# STM32H7B3x register map
File version: 2.2
CPU: CM7 r0p1, little endian, MPU, FPU, 4 interrupt priority bits
Registers are 32-bit, read-write, reset 0x0 unless marked. A register's access mark holds for its fields unless they carry their own. Offsets are from the block's base; [hi:lo] are bit positions.

## USART1 — Universal synchronous asynchronous receiver transmitter
Base 0x40011000
Same registers: USART2 0x40004400, USART3 0x40004800, UART4 0x40004C00, UART5 0x40005000, UART7 0x40007800, UART8 0x40007C00, USART6 0x40011400, UART9 0x40011800, USART10 0x40011C00
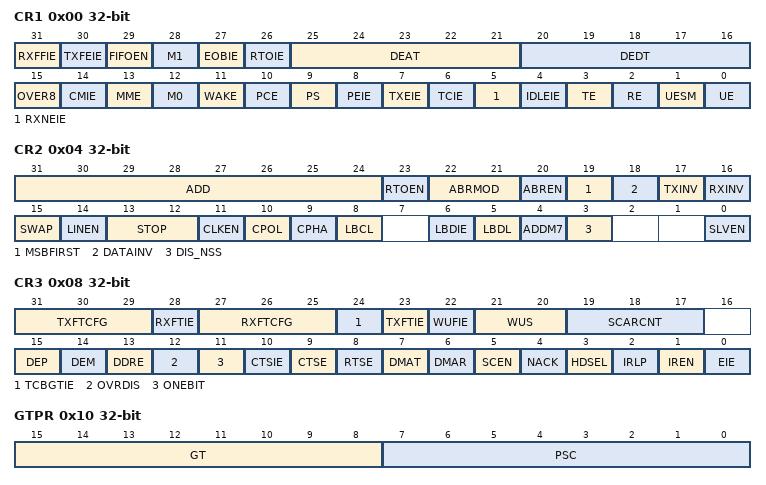
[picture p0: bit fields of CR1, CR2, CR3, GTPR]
0x00 CR1 — Control register 1
  [31] RXFFIE — RXFIFO Full interrupt enable
  [30] TXFEIE — TXFIFO empty interrupt enable
  [29] FIFOEN — FIFO mode enable
  [28] M1 — Word length
    0=M0 (Use M0 to set the data bits); 1=Bit7 (1 start bit, 7 data bits, n stop bits)
  [27] EOBIE — End of Block interrupt enable
    0=Disabled (Interrupt is inhibited); 1=Enabled (A USART interrupt is generated when the EOBF flag is set in the ISR register)
  [26] RTOIE — Receiver timeout interrupt enable
    0=Disabled (Interrupt is inhibited); 1=Enabled (An USART interrupt is generated when the RTOF bit is set in the ISR register)
  [25:21] DEAT — Driver Enable assertion time
  [20:16] DEDT — Driver Enable de-assertion time
  [15] OVER8 — Oversampling mode
    0=Oversampling16 (Oversampling by 16); 1=Oversampling8 (Oversampling by 8)
  [14] CMIE — Character match interrupt enable
    0=Disabled (Interrupt is disabled); 1=Enabled (Interrupt is generated when the CMF bit is set in the ISR register)
  [13] MME — Mute mode enable
    0=Disabled (Receiver in active mode permanently); 1=Enabled (Receiver can switch between mute mode and active mode)
  [12] M0 — Word length
    0=Bit8 (1 start bit, 8 data bits, n stop bits); 1=Bit9 (1 start bit, 9 data bits, n stop bits)
  [11] WAKE — Receiver wakeup method
    0=Idle line; 1=Address mask
  [10] PCE — Parity control enable
    0=Disabled (Parity control disabled); 1=Enabled (Parity control enabled)
  [9] PS — Parity selection
    0=Even parity; 1=Odd (Odd parity)
  [8] PEIE — PE interrupt enable
    0=Disabled (Interrupt is disabled); 1=Enabled (Interrupt is generated whenever PE=1 in the ISR register)
  [7] TXEIE — interrupt enable
    0=Disabled (Interrupt is disabled); 1=Enabled (Interrupt is generated whenever TXE=1 in the ISR register)
  [6] TCIE — Transmission complete interrupt enable
    0=Disabled (Interrupt is disabled); 1=Enabled (Interrupt is generated whenever TC=1 in the ISR register)
  [5] RXNEIE — RXNE interrupt enable
    0=Disabled (Interrupt is disabled); 1=Enabled (Interrupt is generated whenever ORE=1 or RXNE=1 in the ISR register)
  [4] IDLEIE — IDLE interrupt enable
    0=Disabled (Interrupt is disabled); 1=Enabled (Interrupt is generated whenever IDLE=1 in the ISR register)
  [3] TE — Transmitter enable
    0=Disabled (Transmitter is disabled); 1=Enabled (Transmitter is enabled)
  [2] RE — Receiver enable
    0=Disabled (Receiver is disabled); 1=Enabled (Receiver is enabled)
  [1] UESM — USART enable in Stop mode
    0=Disabled (USART not able to wake up the MCU from Stop mode); 1=Enabled (USART able to wake up the MCU from Stop mode)
  [0] UE — USART enable
    0=Disabled (UART is disabled); 1=Enabled (UART is enabled)
0x04 CR2 — Control register 2
  [31:24] ADD — Address of the USART node
  [23] RTOEN — Receiver timeout enable
    0=Disabled (Receiver timeout feature disabled); 1=Enabled (Receiver timeout feature enabled)
  [22:21] ABRMOD — Auto baud rate mode
    0=Start (Measurement of the start bit is used to detect the baud rate); 1=Edge (Falling edge to falling edge measurement); 2=Frame7F (0x7F frame detection); 3=Frame55 (0x55 frame detection)
  [20] ABREN — Auto baud rate enable
    0=Disabled (Auto baud rate detection is disabled); 1=Enabled (Auto baud rate detection is enabled)
  [19] MSBFIRST — Most significant bit first
    0=LSB (data is transmitted/received with data bit 0 first, following the start bit); 1=MSB (data is transmitted/received with MSB (bit 7/8/9) first, following the start bit)
  [18] DATAINV — Binary data inversion
    0=Positive (Logical data from the data register are send/received in positive/direct logic); 1=Negative (Logical data from the data register are send/received in negative/inverse logic)
  [17] TXINV — TX pin active level inversion
    0=Standard (TX pin signal works using the standard logic levels); 1=Inverted (TX pin signal values are inverted)
  [16] RXINV — RX pin active level inversion
    0=Standard (RX pin signal works using the standard logic levels); 1=Inverted (RX pin signal values are inverted)
  [15] SWAP — Swap TX/RX pins
    0=Standard (TX/RX pins are used as defined in standard pinout); 1=Swapped (The TX and RX pins functions are swapped)
  [14] LINEN — LIN mode enable
    0=Disabled (LIN mode disabled); 1=Enabled (LIN mode enabled)
  [13:12] STOP — STOP bits
    0=1 stop bit; 1=Stop0p5 (0.5 stop bit); 2=2 stop bit; 3=Stop1p5 (1.5 stop bit)
  [11] CLKEN — Clock enable
    0=Disabled (CK pin disabled); 1=Enabled (CK pin enabled)
  [10] CPOL — Clock polarity
    0=Low (Steady low value on CK pin outside transmission window); 1=High (Steady high value on CK pin outside transmission window)
  [9] CPHA — Clock phase
    0=First (The first clock transition is the first data capture edge); 1=Second (The second clock transition is the first data capture edge)
  [8] LBCL — Last bit clock pulse
    0=NotOutput (The clock pulse of the last data bit is not output to the CK pin); 1=Output (The clock pulse of the last data bit is output to the CK pin)
  [6] LBDIE — LIN break detection interrupt enable
    0=Disabled (Interrupt is inhibited); 1=Enabled (An interrupt is generated whenever LBDF=1 in the ISR register)
  [5] LBDL — LIN break detection length
    0=Bit10 (10-bit break detection); 1=Bit11 (11-bit break detection)
  [4] ADDM7 — 7-bit Address Detection/4-bit Address Detection
    0=Bit4 (4-bit address detection); 1=Bit7 (7-bit address detection)
  [3] DIS_NSS — When the DSI_NSS bit is set, the NSS pin input is ignored
  [0] SLVEN — Synchronous Slave mode enable
0x08 CR3 — Control register 3
  [31:29] TXFTCFG — TXFIFO threshold configuration
  [28] RXFTIE — RXFIFO threshold interrupt enable
  [27:25] RXFTCFG — Receive FIFO threshold configuration
  [24] TCBGTIE — Transmission Complete before guard time, interrupt enable
  [23] TXFTIE — TXFIFO threshold interrupt enable
  [22] WUFIE — Wakeup from Stop mode interrupt enable
    0=Disabled (Interrupt is inhibited); 1=Enabled (An USART interrupt is generated whenever WUF=1 in the ISR register)
  [21:20] WUS — Wakeup from Stop mode interrupt flag selection
    0=Address (WUF active on address match); 2=Start (WuF active on Start bit detection); 3=RXNE (WUF active on RXNE)
  [19:17] SCARCNT — Smartcard auto-retry count
  [15] DEP — Driver enable polarity selection
    0=High (DE signal is active high); 1=Low (DE signal is active low)
  [14] DEM — Driver enable mode
    0=Disabled (DE function is disabled); 1=Enabled (The DE signal is output on the RTS pin)
  [13] DDRE — DMA Disable on Reception Error
    0=NotDisabled (DMA is not disabled in case of reception error); 1=Disabled (DMA is disabled following a reception error)
  [12] OVRDIS — Overrun Disable
    0=Enabled (Overrun Error Flag, ORE, is set when received data is not read before receiving new data); 1=Disabled (Overrun functionality is disabled. If new data is received while the RXNE flag is still set the ORE flag is not set and the new received data overwrites the previous content of the RDR register)
  [11] ONEBIT — One sample bit method enable
    0=Sample3 (Three sample bit method); 1=Sample1 (One sample bit method)
  [10] CTSIE — CTS interrupt enable
    0=Disabled (Interrupt is inhibited); 1=Enabled (An interrupt is generated whenever CTSIF=1 in the ISR register)
  [9] CTSE — CTS enable
    0=Disabled (CTS hardware flow control disabled); 1=Enabled (CTS mode enabled, data is only transmitted when the CTS input is asserted)
  [8] RTSE — RTS enable
    0=Disabled (RTS hardware flow control disabled); 1=Enabled (RTS output enabled, data is only requested when there is space in the receive buffer)
  [7] DMAT — DMA enable transmitter
    0=Disabled (DMA mode is disabled for transmission); 1=Enabled (DMA mode is enabled for transmission)
  [6] DMAR — DMA enable receiver
    0=Disabled (DMA mode is disabled for reception); 1=Enabled (DMA mode is enabled for reception)
  [5] SCEN — Smartcard mode enable
    0=Disabled (Smartcard Mode disabled); 1=Enabled (Smartcard Mode enabled)
  [4] NACK — Smartcard NACK enable
    0=Disabled (NACK transmission in case of parity error is disabled); 1=Enabled (NACK transmission during parity error is enabled)
  [3] HDSEL — Half-duplex selection
    0=NotSelected (Half duplex mode is not selected); 1=Selected (Half duplex mode is selected)
  [2] IRLP — Ir low-power
    0=Normal mode; 1=Low-power mode
  [1] IREN — Ir mode enable
    0=Disabled (IrDA disabled); 1=Enabled (IrDA enabled)
  [0] EIE — Error interrupt enable
    0=Disabled (Interrupt is inhibited); 1=Enabled (An interrupt is generated when FE=1 or ORE=1 or NF=1 in the ISR register)
0x0C BRR — Baud rate register
  [15:0] BRR — DIV_Mantissa
0x10 GTPR — Guard time and prescaler register
  [15:8] GT — Guard time value
  [7:0] PSC — Prescaler value
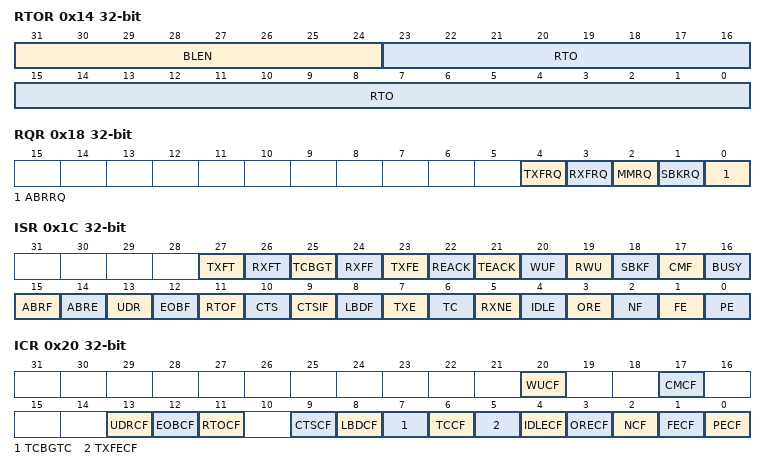
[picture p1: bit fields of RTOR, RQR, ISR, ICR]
0x14 RTOR — Receiver timeout register
  [31:24] BLEN — Block Length
  [23:0] RTO — Receiver timeout value
0x18 RQR wo — Request register
  [4] TXFRQ — Transmit data flush request
    on write: 1=Discard (Set the TXE flags. This allows to discard the transmit data)
  [3] RXFRQ — Receive data flush request
    on write: 1=Discard (clears the RXNE flag. This allows to discard the received data without reading it, and avoid an overrun condition)
  [2] MMRQ — Mute mode request
    on write: 1=Mute (Puts the USART in mute mode and sets the RWU flag)
  [1] SBKRQ — Send break request
    on write: 1=Break (sets the SBKF flag and request to send a BREAK on the line, as soon as the transmit machine is available)
  [0] ABRRQ — Auto baud rate request
    on write: 1=Request (resets the ABRF flag in the USART_ISR and request an automatic baud rate measurement on the next received data frame)
0x1C ISR ro — Interrupt & status register
  [27] TXFT — TXFIFO threshold flag
  [26] RXFT — RXFIFO threshold flag
  [25] TCBGT — Transmission complete before guard time flag
  [24] RXFF — RXFIFO Full
  [23] TXFE — TXFIFO Empty
  [22] REACK
  [21] TEACK
  [20] WUF
  [19] RWU
  [18] SBKF
  [17] CMF
  [16] BUSY
  [15] ABRF
  [14] ABRE
  [13] UDR — SPI slave underrun error flag
  [12] EOBF
  [11] RTOF
  [10] CTS
  [9] CTSIF
  [8] LBDF
  [7] TXE
  [6] TC
  [5] RXNE
  [4] IDLE
  [3] ORE
  [2] NF
  [1] FE
  [0] PE
0x20 ICR wo — Interrupt flag clear register
  [20] WUCF — Wakeup from Stop mode clear flag
    on write: 1=Clears the WUF flag in the ISR register
  [17] CMCF — Character match clear flag
    on write: 1=Clears the CMF flag in the ISR register
  [13] UDRCF — SPI slave underrun clear flag
  [12] EOBCF — End of block clear flag
    on write: 1=Clears the EOBF flag in the ISR register
  [11] RTOCF — Receiver timeout clear flag
    on write: 1=Clears the RTOF flag in the ISR register
  [9] CTSCF — CTS clear flag
    on write: 1=Clears the CTSIF flag in the ISR register
  [8] LBDCF — LIN break detection clear flag
    on write: 1=Clears the LBDF flag in the ISR register
  [7] TCBGTC — Transmission complete before Guard time clear flag
  [6] TCCF — Transmission complete clear flag
    on write: 1=Clears the TC flag in the ISR register
  [5] TXFECF — TXFIFO empty clear flag
  [4] IDLECF — Idle line detected clear flag
    on write: 1=Clears the IDLE flag in the ISR register
  [3] ORECF — Overrun error clear flag
    on write: 1=Clears the ORE flag in the ISR register
  [2] NCF — Noise detected clear flag
    on write: 1=Clears the NF flag in the ISR register
  [1] FECF — Framing error clear flag
    on write: 1=Clears the FE flag in the ISR register
  [0] PECF — Parity error clear flag
    on write: 1=Clears the PE flag in the ISR register
0x24 RDR ro — Receive data register
  [8:0] RDR — Receive data value
0x28 TDR — Transmit data register
  [8:0] TDR — Transmit data value
0x2C PRESC — USART prescaler register
  [3:0] PRESCALER — Clock prescaler
